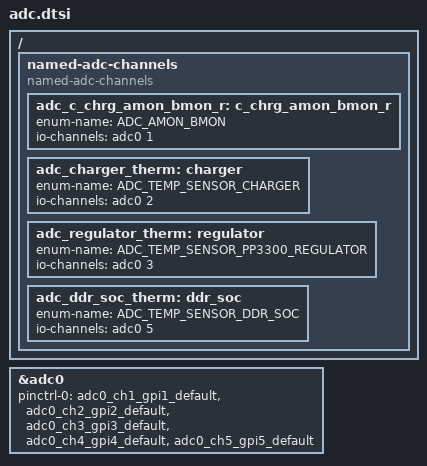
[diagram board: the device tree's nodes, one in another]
/* Copyright 2026 The ChromiumOS Authors
 * Use of this source code is governed by a BSD-style license that can be
 * found in the LICENSE file.
 */

/ {
	named-adc-channels {
		compatible = "named-adc-channels";

		adc_c_chrg_amon_bmon_r: c_chrg_amon_bmon_r {
			enum-name = "ADC_AMON_BMON";
			io-channels = <&adc0 1>;
		};
		adc_charger_therm: charger {
			enum-name = "ADC_TEMP_SENSOR_CHARGER";
			io-channels = <&adc0 2>;
		};
		adc_regulator_therm: regulator {
			enum-name = "ADC_TEMP_SENSOR_PP3300_REGULATOR";
			io-channels = <&adc0 3>;
		};
		adc_ddr_soc_therm: ddr_soc {
			enum-name = "ADC_TEMP_SENSOR_DDR_SOC";
			io-channels = <&adc0 5>;
		};
	};
};

&adc0 {
	status = "okay";
	pinctrl-0 = <&adc0_ch1_gpi1_default
		&adc0_ch2_gpi2_default
		&adc0_ch3_gpi3_default
		&adc0_ch4_gpi4_default
		&adc0_ch5_gpi5_default>;
	pinctrl-names = "default";
};
